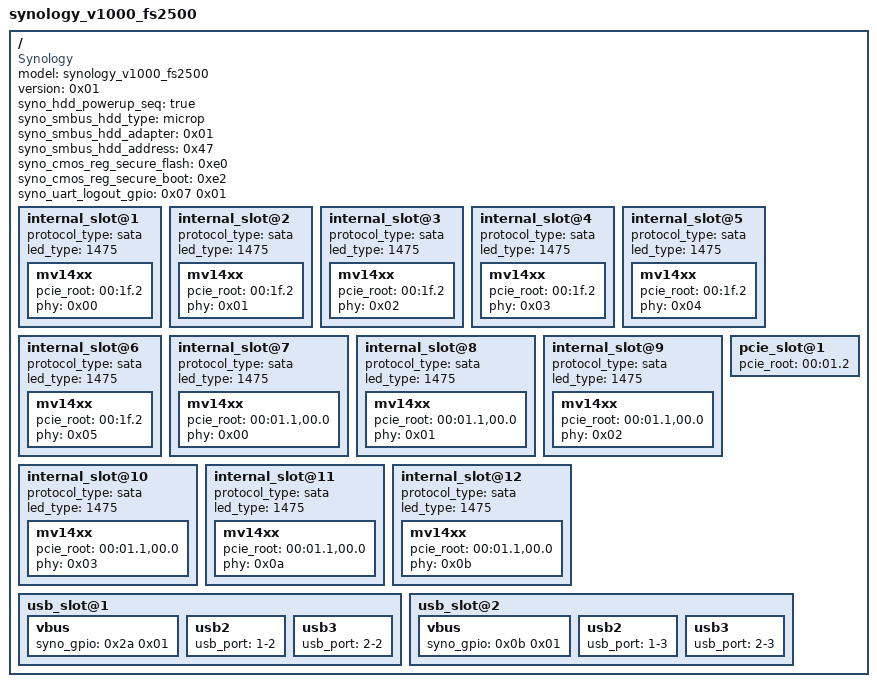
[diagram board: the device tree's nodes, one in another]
/dts-v1/;
/ {
        compatible = "Synology";
        model = "synology_v1000_fs2500";
        version = <0x01>;
        syno_hdd_powerup_seq = "true";
        syno_smbus_hdd_type = "microp";
        syno_smbus_hdd_adapter = <0x01>;
        syno_smbus_hdd_address = <0x47>;
        syno_cmos_reg_secure_flash = <0xe0>;
        syno_cmos_reg_secure_boot = <0xe2>;
        syno_uart_logout_gpio = <0x07 0x01>;
        internal_slot@1 {
                protocol_type = "sata";
                led_type = "1475";
                mv14xx {
                        pcie_root = "00:1f.2";
                        phy = <0x00>;
                };
        };
        internal_slot@2 {
                protocol_type = "sata";
                led_type = "1475";
                mv14xx {
                        pcie_root = "00:1f.2";
                        phy = <0x01>;
                };
        };
        internal_slot@3 {
                protocol_type = "sata";
                led_type = "1475";
                mv14xx {
                        pcie_root = "00:1f.2";
                        phy = <0x02>;
                };
        };
        internal_slot@4 {
                protocol_type = "sata";
                led_type = "1475";
                mv14xx {
                        pcie_root = "00:1f.2";
                        phy = <0x03>;
                };
        };
        internal_slot@5 {
                protocol_type = "sata";
                led_type = "1475";
                mv14xx {
                        pcie_root = "00:1f.2";
                        phy = <0x04>;
                };
        };
        internal_slot@6 {
                protocol_type = "sata";
                led_type = "1475";
                mv14xx {
                        pcie_root = "00:1f.2";
                        phy = <0x05>;
                };
        };
        internal_slot@7 {
                protocol_type = "sata";
                led_type = "1475";
                mv14xx {
                        pcie_root = "00:01.1,00.0";
                        phy = <0x00>;
                };
        };
        internal_slot@8 {
                protocol_type = "sata";
                led_type = "1475";
                mv14xx {
                        pcie_root = "00:01.1,00.0";
                        phy = <0x01>;
                };
        };
        internal_slot@9 {
                protocol_type = "sata";
                led_type = "1475";
                mv14xx {
                        pcie_root = "00:01.1,00.0";
                        phy = <0x02>;
                };
        };
        internal_slot@10 {
                protocol_type = "sata";
                led_type = "1475";
                mv14xx {
                        pcie_root = "00:01.1,00.0";
                        phy = <0x03>;
                };
        };
        internal_slot@11 {
                protocol_type = "sata";
                led_type = "1475";
                mv14xx {
                        pcie_root = "00:01.1,00.0";
                        phy = <0x0a>;
                };
        };
        internal_slot@12 {
                protocol_type = "sata";
                led_type = "1475";
                mv14xx {
                        pcie_root = "00:01.1,00.0";
                        phy = <0x0b>;
                };
        };
        pcie_slot@1 {
                pcie_root = "00:01.2";
        };
        usb_slot@1 {
                vbus {
                        syno_gpio = <0x2a 0x01>;
                };
                usb2 {
                        usb_port = "1-2";
                };
                usb3 {
                        usb_port = "2-2";
                };
        };
        usb_slot@2 {
                vbus {
                        syno_gpio = <0x0b 0x01>;
                };
                usb2 {
                        usb_port = "1-3";
                };
                usb3 {
                        usb_port = "2-3";
                };
        };
};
